VERSION ""

NS_ :

BS_:

BU_: CCU VDC VUM
VAL_TABLE_ vtbSensorReqCause 15 "SNA" 2 "by Request 2" 1 "by Request 1" 0 "normal cycle" ;
VAL_TABLE_ vtbErrorDescription 255 "ERROR" ;

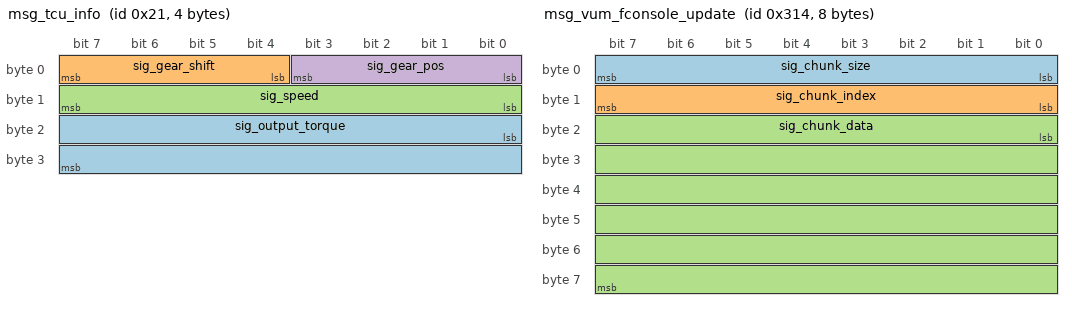
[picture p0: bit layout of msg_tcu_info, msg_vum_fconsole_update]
BO_ 33 msg_tcu_info: 4 CCU
 SG_ sig_output_torque : 16|16@1- (1,0) [-32768|32767] "" Vector__XXX
 SG_ sig_gear_shift : 4|4@1+ (1,0) [0|0] "" Vector__XXX
 SG_ sig_speed : 8|8@1+ (1,0) [0|255] ""  VDC
 SG_ sig_gear_pos : 0|4@1+ (1,0) [0|15] ""  VDC

BO_ 2015 msg_broad_diag_request: 8 CCU
 SG_ sig_broad_diag_request : 0|64@1+ (1,0) [0|0] ""  VDC,VUM

BO_ 1896 msg_vdc_diag_response: 8 VDC
 SG_ sig_vdc_diag_response : 0|64@1+ (1,0) [0|0] ""  CCU

BO_ 1888 msg_vdc_diag_request: 8 CCU
 SG_ sig_vdc_diag_request : 0|64@1+ (1,0) [0|0] ""  VDC

BO_ 1887 msg_vum_diag_response: 8 VUM
 SG_ sig_vum_diag_response : 0|64@1+ (1,0) [0|0] ""  CCU

BO_ 1879 msg_vum_diag_request: 8 CCU
 SG_ sig_vum_diag_request : 0|64@1+ (1,0) [0|0] ""  VUM

BO_ 802 msg_vdc_vum_status: 1 VDC
 SG_ sig_vdc_vum_status : 0|1@1+ (1,0) [0|1] ""  VUM

BO_ 789 msg_vum_vdc_check: 1 VUM
 SG_ sig_vum_vdc_check : 0|1@1+ (1,0) [0|1] ""  VDC

BO_ 788 msg_vum_fconsole_update: 8 VUM
 SG_ sig_chunk_size : 0|8@1+ (1,0) [0|255] ""  CCU
 SG_ sig_chunk_index : 8|8@1+ (1,0) [0|255] ""  CCU
 SG_ sig_chunk_data : 16|48@1+ (1,0) [0|281474976710655] ""  CCU

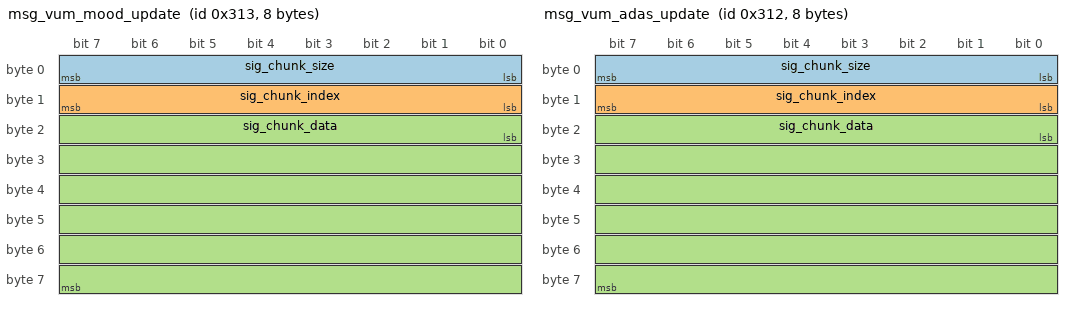
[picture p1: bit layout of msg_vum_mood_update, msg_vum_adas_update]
BO_ 787 msg_vum_mood_update: 8 VUM
 SG_ sig_chunk_size : 0|8@1+ (1,0) [0|255] ""  CCU
 SG_ sig_chunk_index : 8|8@1+ (1,0) [0|255] ""  CCU
 SG_ sig_chunk_data : 16|48@1+ (1,0) [0|281474976710655] ""  CCU

BO_ 786 msg_vum_adas_update: 8 VUM
 SG_ sig_chunk_size : 0|8@1+ (1,0) [0|255] ""  CCU
 SG_ sig_chunk_index : 8|8@1+ (1,0) [0|255] ""  CCU
 SG_ sig_chunk_data : 16|48@1+ (1,0) [0|281474976710655] ""  CCU

BO_ 1300 msg_conn_vdc: 1 CCU
 SG_ sig_conn_vdc : 0|8@1+ (1,0) [0|255] ""  VDC

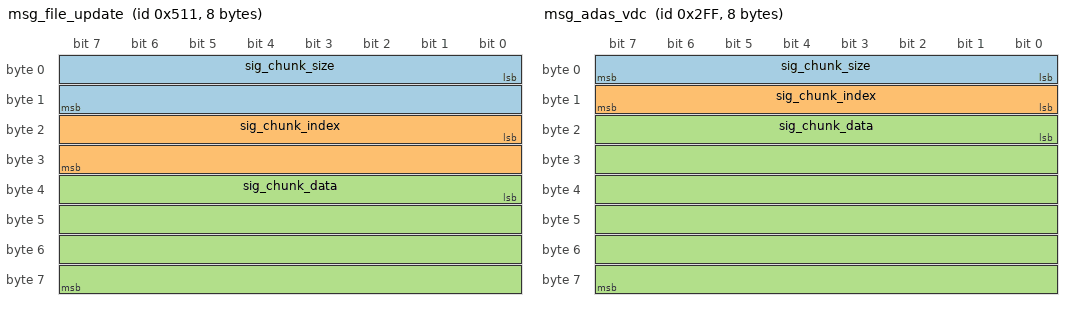
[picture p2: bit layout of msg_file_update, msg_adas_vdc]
BO_ 1297 msg_file_update: 8 CCU
 SG_ sig_chunk_size : 0|16@1+ (1,0) [0|65535] ""  VUM
 SG_ sig_chunk_index : 16|16@1+ (1,0) [0|65535] ""  VUM
 SG_ sig_chunk_data : 32|32@1+ (1,0) [0|4294967295] ""  VUM

BO_ 767 msg_adas_vdc: 8 CCU
 SG_ sig_chunk_size : 0|8@1+ (1,0) [0|255] ""  VDC
 SG_ sig_chunk_index : 8|8@1+ (1,0) [0|255] ""  VDC
 SG_ sig_chunk_data : 16|48@1+ (1,0) [0|281474976710655] ""  VDC

BO_ 531 msg_adas_can_vum: 1 CCU
 SG_ sig_adas_can_vum : 0|1@1+ (1,0) [0|1] ""  VUM

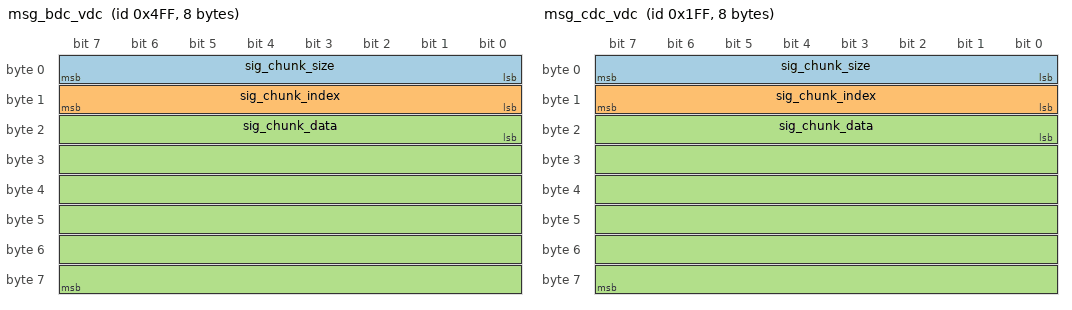
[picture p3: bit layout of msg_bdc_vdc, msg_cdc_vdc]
BO_ 1279 msg_bdc_vdc: 8 CCU
 SG_ sig_chunk_size : 0|8@1+ (1,0) [0|255] ""  VDC
 SG_ sig_chunk_index : 8|8@1+ (1,0) [0|255] ""  VDC
 SG_ sig_chunk_data : 16|48@1+ (1,0) [0|281474976710655] ""  VDC

BO_ 1137 msg_mood_can_vum: 8 CCU
 SG_ sig_mood_can_vum : 0|1@1+ (1,0) [0|1] ""  VUM

BO_ 1064 msg_fconsole_can_vum: 1 CCU
 SG_ sig_fconsole_can_vum : 0|1@1+ (1,0) [0|1] ""  VUM

BO_ 1057 msg_fconsole_parking: 1 CCU
 SG_ sig_console_parking_brake : 0|1@1+ (1,0) [0|1] ""  VUM

BO_ 511 msg_cdc_vdc: 8 CCU
 SG_ sig_chunk_size : 0|8@1+ (1,0) [0|255] ""  VDC
 SG_ sig_chunk_index : 8|8@1+ (1,0) [0|255] ""  VDC
 SG_ sig_chunk_data : 16|48@1+ (1,0) [0|281474976710655] ""  VDC

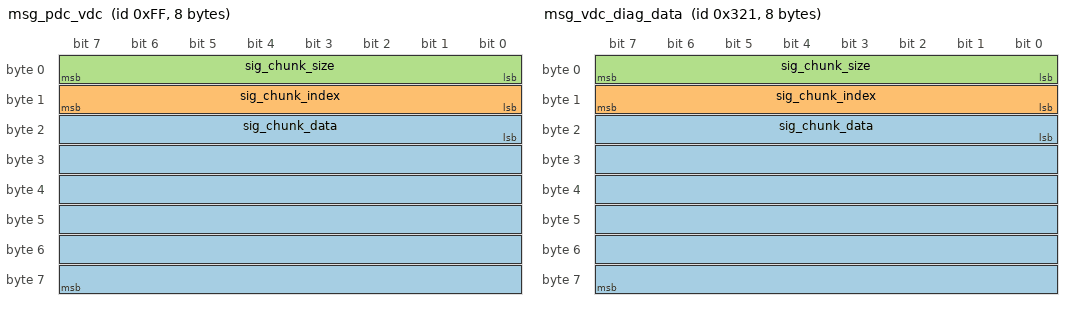
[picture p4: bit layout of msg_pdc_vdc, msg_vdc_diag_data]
BO_ 255 msg_pdc_vdc: 8 CCU
 SG_ sig_chunk_data : 16|48@1+ (1,0) [0|281474976710655] ""  VDC
 SG_ sig_chunk_index : 8|8@1+ (1,0) [0|255] ""  VDC
 SG_ sig_chunk_size : 0|8@1+ (1,0) [0|255] ""  VDC

BO_ 801 msg_vdc_diag_data: 8 VDC
 SG_ sig_chunk_data : 16|48@1+ (1,0) [0|1099511627775] ""  CCU
 SG_ sig_chunk_index : 8|8@1+ (1,0) [0|255] ""  CCU
 SG_ sig_chunk_size : 0|8@1+ (1,0) [0|255] ""  CCU

BO_ 785 msg_vum_check_update: 2 VUM
 SG_ sig_check_status : 8|4@1+ (1,0) [0|15] ""  CCU
 SG_ sig_target_ecu : 0|8@1+ (1,0) [0|255] ""  CCU

BO_ 799 msg_vum_vdc: 6 VUM
 SG_ sig_vum_update_version : 32|16@1+ (1,0) [0|65535] ""  VDC
 SG_ sig_vum_dtc : 0|32@1+ (1,0) [0|4294967295] ""  VDC

BO_ 798 msg_vum_alive: 1 VUM
 SG_ sig_vum_alive : 0|1@1+ (1,0) [0|1] ""  VDC

BA_DEF_  "DatabaseVersion" STRING ;
BA_DEF_  "Manufacturer" STRING ;
BA_DEF_ BU_  "NodeLayerModules" STRING ;
BA_DEF_  "BusType" STRING ;
BA_DEF_ SG_  "GenSigSendType" ENUM  "Cyclic","OnWrite","OnWriteWithRepetition","OnChange","OnChangeWithRepetition","IfActive","IfActiveWithRepetition","NoSigSendType","NotUsed","NotUsed","NotUsed","NotUsed","NotUsed";
BA_DEF_ BO_  "GenMsgSendType" ENUM  "Cyclic","NotUsed","NotUsed","NotUsed","NotUsed","Cyclic","NotUsed","IfActive","NoMsgSendType","NotUsed","vector_leerstring";
BA_DEF_ BO_  "GenMsgCycleTime" INT 0 50000;
BA_DEF_ BO_  "GenMsgCycleTimeFast" INT 0 50000;
BA_DEF_ BO_  "GenMsgILSupport" ENUM  "No","Yes";
BA_DEF_DEF_  "DatabaseVersion" "";
BA_DEF_DEF_  "Manufacturer" "Vector";
BA_DEF_DEF_  "NodeLayerModules" "CANoeILNLVector.dll";
BA_DEF_DEF_  "BusType" "CAN";
BA_DEF_DEF_  "GenSigSendType" "Cyclic";
BA_DEF_DEF_  "GenMsgSendType" "NoMsgSendType";
BA_DEF_DEF_  "GenMsgCycleTime" 200;
BA_DEF_DEF_  "GenMsgCycleTimeFast" 20;
BA_DEF_DEF_  "GenMsgILSupport" "Yes";
BA_ "DatabaseVersion" "1.1";
